# R9A02G021 register map
Vendor: Renesas Electronics Corporation; Series: RISC-V; File version: 1.10.00 + 202304131714_CPU
CPU: other r0p0, little endian, no MPU, no FPU, VTOR, 4 interrupt priority bits, 32 interrupts
Registers are 8-bit, read-write, reset 0x0 unless marked. A register's access mark holds for its fields unless they carry their own. Offsets are from the block's base; [hi:lo] are bit positions; {n}, {i} and the like mark numbered series; 'fields as' and 'values as' point back to an identical list.

## TML32 — 32-bit Interval Timer
Base 0x40092200
{0x0+2i} ITLCMP0{i} (i=0..1) 16-bit reset 0xFFFF — Interval Timer Compare Registers 0{i}
  [15:0] CMP16 — 16-bit timer setting compare data for unit n
0x04 ITLCAP00 16-bit ro — Interval Timer Capture Register 00
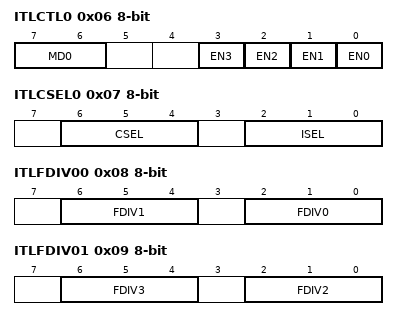
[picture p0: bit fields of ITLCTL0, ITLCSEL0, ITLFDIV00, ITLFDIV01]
0x06 ITLCTL0 — Interval Timer Control Register
  [7:6] MD0 — Selection of 8-bit, 16-bit, or 32-bit counter mode
    0=The interval timer operates in 8-bit counter mode; 1=The interval timer operates in 16-bit counter mode (channel 0 is connected with channel 1 and channel 2 is connected with channel 3); 2=The interval timer operates in 32-bit counter mode (channels 0 to 3 are connected); 3=Setting prohibited
  [3] EN3 — 8-bit counter mode: ITL013 count enable
    0=Counting stops; 1=Counting begins
  [2] EN2 — 8-bit counter mode: ITL012 count enable
    0=Counting stops; 1=Counting begins
  [1] EN1 — 8-bit counter mode: ITL001 count enable
    0=Counting stops; 1=Counting begins
  [0] EN0 — 8-bit counter mode: ITL000 count enable
    0=Counting stops; 1=Counting begins
0x07 ITLCSEL0 — Interval Timer Clock Select Register 0
  [6:4] CSEL — Selection of interval timer count clock for capturing (fITL1)
    0=Counting stops; 1=TML32HCLK; 2=TML32MOCLK; 3=TML32MCLK; 4=TML32LCLK/TML32SCLK; 5=Event input from the ELC; other=Others (Setting prohibited)
  [2:0] ISEL — Selection of interval timer count clock (fITL0)
    values as CSEL
0x08 ITLFDIV00 — Interval Timer Frequency Division Register 0
  [6:4] FDIV1 — 8-bit counter mode: Counter clock for ITL001
    0=fITL0; 1=fITL0/2; 2=fITL0/4; 3=fITL0/8; 4=fITL0/16; 5=fITL0/32; 6=fITL0/64; 7=fITL0/128
  [2:0] FDIV0 — 8-bit counter mode: Counter clock for ITL000
    values as FDIV1
0x09 ITLFDIV01 — Interval Timer Frequency Division Register 1
  [6:4] FDIV3 — 8-bit counter mode: Counter clock for ITL013
    values as ITLFDIV00.FDIV1
  [2:0] FDIV2 — 8-bit counter mode: Counter clock for ITL012
    values as ITLFDIV00.FDIV1
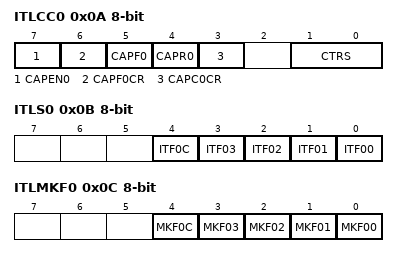
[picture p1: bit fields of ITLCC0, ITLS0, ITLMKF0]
0x0A ITLCC0 — Interval Timer Capture Control Register 0
  [7] CAPEN0 — Capture enable
    0=Capturing is disabled; 1=Capturing is enabled
  [6] CAPF0CR — Capture completion flag clear
    0=The value of the capture completion flag CAPF0 is held; 1=The value of the capture completion flag CAPF0 is cleared
  [5] CAPF0 ro — Capture completion flag
    0=Capturing has not been completed; 1=Capturing has been completed. This flag is set to 1 after a capture trigger selected in the CTRS[1:0] bits is generated and the captured data is stored in ITLCAP00. Writing 1 to the CAPF0CR bit clears this flag to 0.
  [4] CAPR0 — Software capture trigger
    0=Trigger operation does not proceed; 1=A software trigger for capturing is generated
  [3] CAPC0CR — Selection of capture counter clearing after capturing
    0=The capture counter value is held after the completion of capturing; 1=The capture counter value is cleared after the completion of capturing
  [1:0] CTRS — Selection of capture trigger
    0=Software trigger; 1=Interrupt on compare match with ITLCMP01; 2=TML32LCLK/TML32SCLK (rising edge); 3=Event input from ELC (rising edge)
0x0B ITLS0 — Interval Timer Status Register
  [4] ITF0C — Capture detection flag
    0=Completion of capturing has not been detected; 1=Completion of capturing has been detected
  [n] ITF{n:02} (n=0..3) — Compare match detection flag for channel {n}
    0=A compare match signal has not been detected in channel {n}; 1=A compare match signal has been detected in channel {n}
0x0C ITLMKF0 — Interval Timer Match Detection Mask Register
  [4] MKF0C — Mask for capture detection status flag
    0=ITLS0.ITF0C is not masked; 1=ITLS0.ITF0C is masked
  [n] MKF{n:02} (n=0..3) — Mask for compare match status flag for channel {n}
    0=ITLS0.ITF{n:02} is not masked; 1=ITLS0.ITF{n:02} is masked
